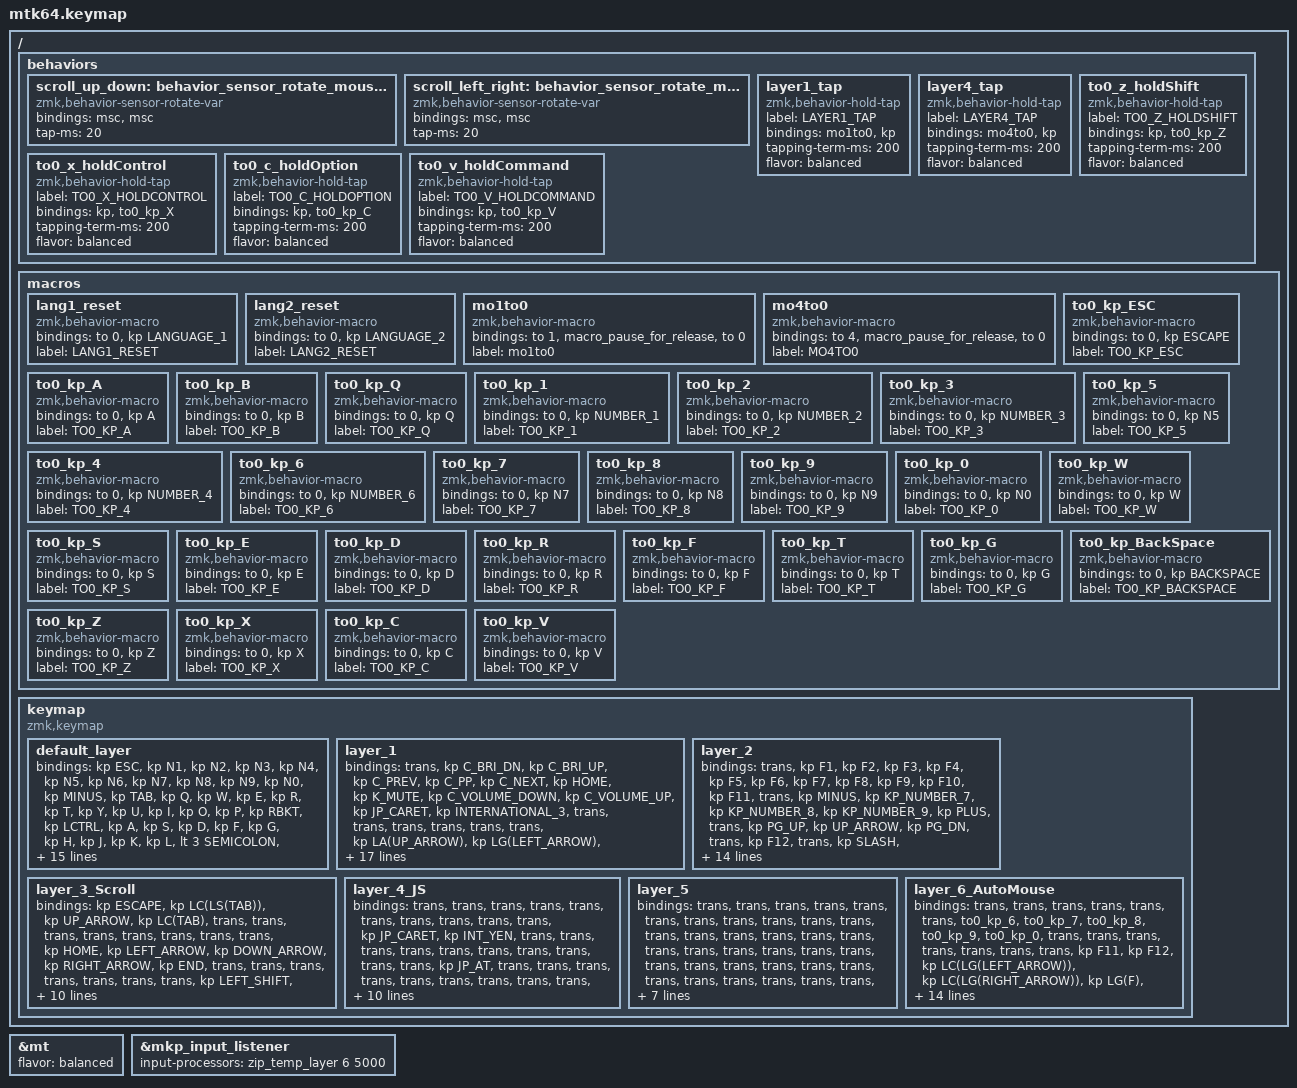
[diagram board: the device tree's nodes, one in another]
#include <input/processors.dtsi>
#include <behaviors.dtsi>
#include <dt-bindings/zmk/keys.h>
#include <dt-bindings/zmk/pointing.h>
#include "keycode_japanese.h"

// スクロール量の設定

#define ZMK_POINTING_DEFAULT_SCRL_VAL 100

&mt { flavor = "balanced"; };

&mkp_input_listener { input-processors = <&zip_temp_layer 6 5000>; };

/ {
    behaviors {
        // 垂直スクロール用のbehaviorの設定

        scroll_up_down: behavior_sensor_rotate_mouse_wheel_up_down {
            compatible = "zmk,behavior-sensor-rotate-var";
            #sensor-binding-cells = <2>;
            bindings = <&msc>, <&msc>;

            tap-ms = <20>; // スクロールのタップ時間
        };

        // 水平スクロール用のbehaviorの設定

        scroll_left_right: behavior_sensor_rotate_mouse_wheel_left_right {
            compatible = "zmk,behavior-sensor-rotate-var";
            #sensor-binding-cells = <2>;
            bindings = <&msc>, <&msc>;

            tap-ms = <20>; // スクロールのタップ時間
        };

        layer1_tap: layer1_tap {
            compatible = "zmk,behavior-hold-tap";
            label = "LAYER1_TAP";
            bindings = <&mo1to0>, <&kp>;

            #binding-cells = <2>;
            tapping-term-ms = <200>;
            flavor = "balanced";
        };

        layer4_tap: layer4_tap {
            compatible = "zmk,behavior-hold-tap";
            label = "LAYER4_TAP";
            bindings = <&mo4to0>, <&kp>;

            #binding-cells = <2>;
            tapping-term-ms = <200>;
            flavor = "balanced";
        };

        to0_z_holdShift: to0_z_holdShift {
            compatible = "zmk,behavior-hold-tap";
            label = "TO0_Z_HOLDSHIFT";
            bindings = <&kp>, <&to0_kp_Z>;

            #binding-cells = <2>;
            tapping-term-ms = <200>;
            flavor = "balanced";
        };

        to0_x_holdControl: to0_x_holdControl {
            compatible = "zmk,behavior-hold-tap";
            label = "TO0_X_HOLDCONTROL";
            bindings = <&kp>, <&to0_kp_X>;

            #binding-cells = <2>;
            tapping-term-ms = <200>;
            flavor = "balanced";
        };

        to0_c_holdOption: to0_c_holdOption {
            compatible = "zmk,behavior-hold-tap";
            label = "TO0_C_HOLDOPTION";
            bindings = <&kp>, <&to0_kp_C>;

            #binding-cells = <2>;
            tapping-term-ms = <200>;
            flavor = "balanced";
        };

        to0_v_holdCommand: to0_v_holdCommand {
            compatible = "zmk,behavior-hold-tap";
            label = "TO0_V_HOLDCOMMAND";
            bindings = <&kp>, <&to0_kp_V>;

            #binding-cells = <2>;
            tapping-term-ms = <200>;
            flavor = "balanced";
        };
    };
};

/ {
    macros {
        lang1_reset: lang1_reset {
            compatible = "zmk,behavior-macro";
            #binding-cells = <0>;
            bindings = <&to 0 &kp LANGUAGE_1>;
            label = "LANG1_RESET";
        };

        lang2_reset: lang2_reset {
            compatible = "zmk,behavior-macro";
            #binding-cells = <0>;
            bindings = <&to 0 &kp LANGUAGE_2>;
            label = "LANG2_RESET";
        };

        mo1to0: mo1to0 {
            compatible = "zmk,behavior-macro";
            #binding-cells = <0>;
            bindings = <&to 1>, <&macro_pause_for_release>, <&to 0>;

            label = "mo1to0";
        };

        mo4to0: mo4to0 {
            compatible = "zmk,behavior-macro";
            #binding-cells = <0>;
            bindings = <&to 4>, <&macro_pause_for_release>, <&to 0>;

            label = "MO4TO0";
        };

        to0_kp_ESC: to0_kp_ESC {
            compatible = "zmk,behavior-macro";
            #binding-cells = <0>;
            bindings = <&to 0 &kp ESCAPE>;
            label = "TO0_KP_ESC";
        };

        to0_kp_A: to0_kp_A {
            compatible = "zmk,behavior-macro";
            #binding-cells = <0>;
            bindings = <&to 0 &kp A>;
            label = "TO0_KP_A";
        };

        to0_kp_B: to0_kp_B {
            compatible = "zmk,behavior-macro";
            #binding-cells = <0>;
            bindings = <&to 0 &kp B>;
            label = "TO0_KP_B";
        };

        to0_kp_Q: to0_kp_Q {
            compatible = "zmk,behavior-macro";
            #binding-cells = <0>;
            bindings = <&to 0 &kp Q>;
            label = "TO0_KP_Q";
        };

        to0_kp_1: to0_kp_1 {
            compatible = "zmk,behavior-macro";
            #binding-cells = <0>;
            bindings = <&to 0 &kp NUMBER_1>;
            label = "TO0_KP_1";
        };

        to0_kp_2: to0_kp_2 {
            compatible = "zmk,behavior-macro";
            #binding-cells = <0>;
            bindings = <&to 0 &kp NUMBER_2>;
            label = "TO0_KP_2";
        };

        to0_kp_3: to0_kp_3 {
            compatible = "zmk,behavior-macro";
            #binding-cells = <0>;
            bindings = <&to 0 &kp NUMBER_3>;
            label = "TO0_KP_3";
        };

        to0_kp_4: to0_kp_4 {
            compatible = "zmk,behavior-macro";
            #binding-cells = <0>;
            bindings = <&to 0 &kp NUMBER_4>;
            label = "TO0_KP_4";
        };

        to0_kp_5: to0_kp_5 {
            compatible = "zmk,behavior-macro";
            #binding-cells = <0>;
            bindings = <&to 0 &kp N5>;
            label = "TO0_KP_5";
        };

        to0_kp_6: to0_kp_6 {
            compatible = "zmk,behavior-macro";
            #binding-cells = <0>;
            bindings = <&to 0 &kp NUMBER_6>;
            label = "TO0_KP_6";
        };

        to0_kp_7: to0_kp_7 {
            compatible = "zmk,behavior-macro";
            #binding-cells = <0>;
            bindings = <&to 0 &kp N7>;
            label = "TO0_KP_7";
        };

        to0_kp_8: to0_kp_8 {
            compatible = "zmk,behavior-macro";
            #binding-cells = <0>;
            bindings = <&to 0 &kp N8>;
            label = "TO0_KP_8";
        };

        to0_kp_9: to0_kp_9 {
            compatible = "zmk,behavior-macro";
            #binding-cells = <0>;
            bindings = <&to 0 &kp N9>;
            label = "TO0_KP_9";
        };

        to0_kp_0: to0_kp_0 {
            compatible = "zmk,behavior-macro";
            #binding-cells = <0>;
            bindings = <&to 0 &kp N0>;
            label = "TO0_KP_0";
        };

        to0_kp_W: to0_kp_W {
            compatible = "zmk,behavior-macro";
            #binding-cells = <0>;
            bindings = <&to 0 &kp W>;
            label = "TO0_KP_W";
        };

        to0_kp_S: to0_kp_S {
            compatible = "zmk,behavior-macro";
            #binding-cells = <0>;
            bindings = <&to 0 &kp S>;
            label = "TO0_KP_S";
        };

        to0_kp_E: to0_kp_E {
            compatible = "zmk,behavior-macro";
            #binding-cells = <0>;
            bindings = <&to 0 &kp E>;
            label = "TO0_KP_E";
        };

        to0_kp_D: to0_kp_D {
            compatible = "zmk,behavior-macro";
            #binding-cells = <0>;
            bindings = <&to 0 &kp D>;
            label = "TO0_KP_D";
        };

        to0_kp_R: to0_kp_R {
            compatible = "zmk,behavior-macro";
            #binding-cells = <0>;
            bindings = <&to 0 &kp R>;
            label = "TO0_KP_R";
        };

        to0_kp_F: to0_kp_F {
            compatible = "zmk,behavior-macro";
            #binding-cells = <0>;
            bindings = <&to 0 &kp F>;
            label = "TO0_KP_F";
        };

        to0_kp_T: to0_kp_T {
            compatible = "zmk,behavior-macro";
            #binding-cells = <0>;
            bindings = <&to 0 &kp T>;
            label = "TO0_KP_T";
        };

        to0_kp_G: to0_kp_G {
            compatible = "zmk,behavior-macro";
            #binding-cells = <0>;
            bindings = <&to 0 &kp G>;
            label = "TO0_KP_G";
        };

        to0_kp_BackSpace: to0_kp_BackSpace {
            compatible = "zmk,behavior-macro";
            #binding-cells = <0>;
            bindings = <&to 0 &kp BACKSPACE>;
            label = "TO0_KP_BACKSPACE";
        };

        to0_kp_Z: to0_kp_Z {
            compatible = "zmk,behavior-macro";
            #binding-cells = <0>;
            bindings = <&to 0 &kp Z>;
            label = "TO0_KP_Z";
        };

        to0_kp_X: to0_kp_X {
            compatible = "zmk,behavior-macro";
            #binding-cells = <0>;
            bindings = <&to 0 &kp X>;
            label = "TO0_KP_X";
        };

        to0_kp_C: to0_kp_C {
            compatible = "zmk,behavior-macro";
            #binding-cells = <0>;
            bindings = <&to 0 &kp C>;
            label = "TO0_KP_C";
        };

        to0_kp_V: to0_kp_V {
            compatible = "zmk,behavior-macro";
            #binding-cells = <0>;
            bindings = <&to 0 &kp V>;
            label = "TO0_KP_V";
        };
    };

    keymap {
        compatible = "zmk,keymap";

        default_layer {
            bindings = <
&kp ESC  &kp N1  &kp N2  &kp N3  &kp N4  &kp N5  &kp N6  &kp N7  &kp N8  &kp N9  &kp N0  &kp MINUS  &kp TAB  &kp Q  &kp W  &kp E  &kp R  &kp T  &kp Y  &kp U  &kp I  &kp O  &kp P  &kp RBKT  &kp LCTRL  &kp A  &kp S  &kp D  &kp F  &kp G  &kp H  &kp J  &kp K  &kp L  &lt 3 SEMICOLON  &kp NUHS  &kp LSHFT  &mt LEFT_SHIFT Z  &mt LEFT_CONTROL X  &mt LEFT_ALT C  &mt LEFT_GUI V  &lt 3 B  &kp LC(BACKSPACE)  &kp BACKSPACE  &kp N  &mt RIGHT_COMMAND M  &mt RIGHT_ALT COMMA  &mt RIGHT_CONTROL DOT  &mt RIGHT_SHIFT SLASH  &kp RETURN  &kp LALT  &kp LGUI  &layer1_tap 0 SPACE  &lt 2 SPACE  &kp BSPC  &layer4_tap 0 SPACE  &kp JP_UNDER  &kp RIGHT_SHIFT  &tog 2  &kp ENTER  &none  &lt 1 ENTER  &kp ENTER  &tog 2  &kp LANGUAGE_2  &kp LANGUAGE_1  &mo 1  &mo 2  &mo 3  &mo 1  &mo 2  &mo 3  &mo 1  &mo 2  &mo 3
            >;

            sensor-bindings =
                <&inc_dec_kp C_VOLUME_DOWN C_VOLUME_UP>,
                <&scroll_up_down SCRL_UP SCRL_DOWN>;
        };

        layer_1 {
            bindings = <
&trans  &kp C_BRI_DN  &kp C_BRI_UP  &kp C_PREV  &kp C_PP  &kp C_NEXT  &kp HOME  &kp K_MUTE  &kp C_VOLUME_DOWN  &kp C_VOLUME_UP  &kp JP_CARET  &kp INTERNATIONAL_3  &trans  &trans  &trans  &trans  &trans  &trans  &kp LA(UP_ARROW)  &kp LG(LEFT_ARROW)  &kp LG(RIGHT_ARROW)  &kp LA(DOWN_ARROW)  &kp UP_ARROW  &kp JP_AT  &trans  &trans  &trans  &trans  &kp LC(LEFT_ARROW)  &kp LC(RIGHT_ARROW)  &kp LA(LEFT_ARROW)  &kp LEFT_ARROW  &kp RIGHT_ARROW  &kp LA(RIGHT_ARROW)  &kp DOWN_ARROW  &kp JP_COLON  &trans  &kp LEFT_SHIFT  &kp LEFT_CONTROL  &kp LEFT_ALT  &kp LEFT_GUI  &kp LC(DOWN_ARROW)  &kp LC(UP_ARROW)  &trans  &kp LS(LG(NUMBER_3))  &kp LG(LS(NUMBER_4))  &kp LG(LS(NUMBER_5))  &kp LG(LS(NUMBER_6))  &kp LG(LS(NUMBER_7))  &kp LS(LG(NUMBER_8))  &trans  &trans  &trans  &trans  &trans  &kp LA(SPACE)  &trans  &trans  &trans  &trans  &trans  &trans  &trans  &trans  &trans  &trans  &trans  &trans  &trans  &trans  &trans  &trans  &trans  &trans  &trans
            >;
        };

        layer_2 {
            bindings = <
&trans  &kp F1  &kp F2  &kp F3  &kp F4  &kp F5  &kp F6  &kp F7  &kp F8  &kp F9  &kp F10  &kp F11  &trans  &kp MINUS  &kp KP_NUMBER_7  &kp KP_NUMBER_8  &kp KP_NUMBER_9  &kp PLUS  &trans  &kp PG_UP  &kp UP_ARROW  &kp PG_DN  &trans  &kp F12  &trans  &kp SLASH  &kp KP_NUMBER_4  &kp KP_NUMBER_5  &kp KP_NUMBER_6  &kp ASTERISK  &kp HOME  &kp LEFT_ARROW  &kp DOWN_ARROW  &kp RIGHT_ARROW  &kp END  &trans  &trans  &mt LEFT_SHIFT KP_NUMBER_0  &kp KP_NUMBER_1  &kp KP_NUMBER_2  &kp KP_NUMBER_3  &kp PERIOD  &kp EQUAL  &mkp MB4  &mkp MB5  &mkp MB1  &mkp MB2  &mkp MB3  &trans  &trans  &trans  &trans  &trans  &trans  &trans  &trans  &trans  &trans  &trans  &trans  &trans  &trans  &trans  &trans  &trans  &trans  &trans  &trans  &trans  &trans  &trans  &trans  &trans  &trans  &trans
            >;

            sensor-bindings = <
                &inc_dec_kp TAB LS(TAB) 
                &inc_dec_kp PG_UP PG_DN
            >;
        };

        layer_3_Scroll {
            bindings = <
&kp ESCAPE  &kp LC(LS(TAB))  &kp UP_ARROW  &kp LC(TAB)  &trans  &trans  &trans  &trans  &trans  &trans  &trans  &trans  &kp HOME  &kp LEFT_ARROW  &kp DOWN_ARROW  &kp RIGHT_ARROW  &kp END  &trans  &trans  &trans  &trans  &trans  &trans  &trans  &kp LEFT_SHIFT  &kp LG(LS(LEFT_ARROW))  &trans  &kp LG(LS(RIGHT_ARROW))  &trans  &trans  &trans  &trans  &trans  &trans  &trans  &trans  &trans  &trans  &trans  &trans  &trans  &trans  &trans  &trans  &trans  &trans  &trans  &trans  &trans  &trans  &trans  &trans  &trans  &trans  &trans  &trans  &trans  &trans
            >;

            sensor-bindings =
                <&scroll_left_right SCRL_RIGHT SCRL_LEFT>,
                <&scroll_up_down SCRL_DOWN SCRL_UP>;
        };

        layer_4_JS {
            bindings = <
&trans  &trans  &trans  &trans  &trans  &trans  &trans  &trans  &trans  &trans  &kp JP_CARET  &kp INT_YEN  &trans  &trans  &trans  &trans  &trans  &trans  &trans  &trans  &trans  &trans  &kp JP_AT  &trans  &trans  &trans  &trans  &trans  &trans  &trans  &trans  &trans  &trans  &trans  &kp JP_COLON  &trans  &trans  &trans  &trans  &trans  &trans  &trans  &trans  &trans  &trans  &trans  &trans  &trans  &trans  &trans  &trans  &trans  &kp LG(LA(LS(NUMBER_2)))  &trans  &trans  &trans  &trans  &trans  &trans  &trans  &trans  &trans  &trans  &trans  &kp LG(LA(LS(NUMBER_1)))  &trans  &trans  &trans  &trans  &trans  &trans  &trans  &trans  &trans  &trans
            >;
        };

        layer_5 {
            bindings = <
&trans  &trans  &trans  &trans  &trans  &trans  &trans  &trans  &trans  &trans  &trans  &trans  &trans  &trans  &trans  &trans  &trans  &trans  &trans  &trans  &trans  &trans  &trans  &trans  &trans  &trans  &trans  &trans  &trans  &trans  &trans  &trans  &trans  &trans  &trans  &trans  &trans  &trans  &trans  &trans  &trans  &trans  &trans  &trans  &trans  &trans  &trans  &trans  &trans  &trans  &trans  &trans  &trans  &trans  &trans  &trans  &trans  &trans  &trans  &trans  &trans  &trans  &trans  &trans  &trans  &trans  &trans  &trans  &trans  &trans  &trans  &trans  &trans  &trans  &trans
            >;
        };

        layer_6_AutoMouse {
            bindings = <
&trans  &trans  &trans  &trans  &trans  &trans  &to0_kp_6  &to0_kp_7  &to0_kp_8  &to0_kp_9  &to0_kp_0  &trans  &trans  &trans  &trans  &trans  &trans  &trans  &kp F11  &kp F12  &kp LC(LG(LEFT_ARROW))  &kp LC(LG(RIGHT_ARROW))  &kp LG(F)  &kp LG(LS(F))  &trans  &trans  &trans  &trans  &trans  &trans  &mkp MB4  &mkp MB1  &mkp MB2  &mkp MB5  &mo 3  &kp LC(UP_ARROW)  &trans  &trans  &trans  &trans  &trans  &mo 3  &trans  &to0_kp_BackSpace  &kp LG(R)  &mt (RIGHT_GUI) LG(C)  &mt (RIGHT_ALT) LG(V)  &mt (LEFT_CONTROL) LG(Z)  &mt (RIGHT_SHIFT) LG(LS(Z))  &trans  &trans  &trans  &trans  &trans  &trans  &trans  &kp LC(UP_ARROW)  &kp LC(DOWN_ARROW)  &trans  &trans  &trans  &trans  &trans  &trans  &lang2_reset  &lang1_reset  &trans  &trans  &trans  &trans  &trans  &trans  &trans  &trans  &trans
            >;
        };
    };
};
